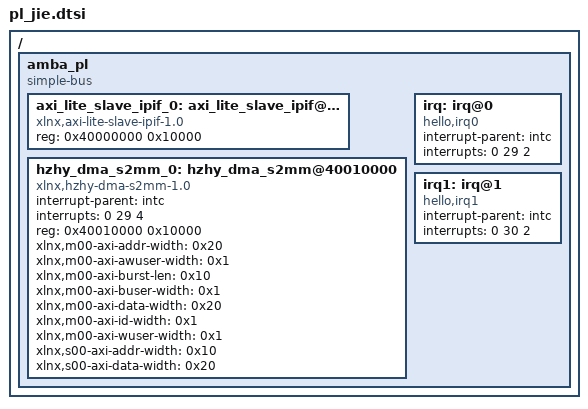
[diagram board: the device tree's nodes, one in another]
/*
 * CAUTION: This file is automatically generated by Xilinx.
 * Version:  
 * Today is: Wed Oct 09 16:08:07 2019
*/


/ {
	amba_pl: amba_pl {
		#address-cells = <1>;
		#size-cells = <1>;
		compatible = "simple-bus";
		ranges ;
		axi_lite_slave_ipif_0: axi_lite_slave_ipif@40000000 {
			compatible = "xlnx,axi-lite-slave-ipif-1.0";
			reg = <0x40000000 0x10000>;
		};
		hzhy_dma_s2mm_0: hzhy_dma_s2mm@40010000 {
			compatible = "xlnx,hzhy-dma-s2mm-1.0";
			interrupt-parent = <&intc>;
			interrupts = <0 29 4>;
			reg = <0x40010000 0x10000>;
			xlnx,m00-axi-addr-width = <0x20>;
			xlnx,m00-axi-awuser-width = <0x1>;
			xlnx,m00-axi-burst-len = <0x10>;
			xlnx,m00-axi-buser-width = <0x1>;
			xlnx,m00-axi-data-width = <0x20>;
			xlnx,m00-axi-id-width = <0x1>;
			xlnx,m00-axi-wuser-width = <0x1>;
			xlnx,s00-axi-addr-width = <0x10>;
			xlnx,s00-axi-data-width = <0x20>;
		};
		irq: irq@0{
                        compatible = "hello,irq0";
                        interrupt-parent = <&intc>;
                        interrupts = <0 29 2>;
                };
        irq1: irq@1{
                        compatible = "hello,irq1";
                        interrupt-parent = <&intc>;
                        interrupts = <0 30 2>;
                };
	
	};
};
